# CH572SFR register map
Vendor: WCH Ltd.; Series: CH572; File version: 1.1
CPU: RISC-V r0p0, little endian, no MPU, no FPU, 2 interrupt priority bits
Registers are 32-bit, read-write, reset 0x0 unless marked. A register's access mark holds for its fields unless they carry their own. Offsets are from the block's base; [hi:lo] are bit positions.

## TMR — Timer register
Base 0x40002400
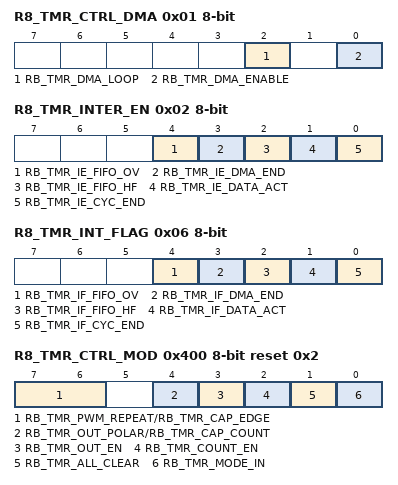
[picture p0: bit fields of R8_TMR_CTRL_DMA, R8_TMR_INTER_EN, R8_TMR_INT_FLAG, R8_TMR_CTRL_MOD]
0x01 R8_TMR_CTRL_DMA 8-bit — RO/WO, DMA control register
  [2] RB_TMR_DMA_LOOP — RW, Enable bit for DMA address loop function
  [0] RB_TMR_DMA_ENABLE — RW, DMA function enable bit
0x02 R8_TMR_INTER_EN 8-bit — RW, TMR interrupt enable
  [4] RB_TMR_IE_FIFO_OV — RW, enable interrupt for timer FIFO overflow
  [3] RB_TMR_IE_DMA_END — RW, enable interrupt for timer1/2 DMA completion
  [2] RB_TMR_IE_FIFO_HF — RW, enable interrupt for timer FIFO half (capture fifo >=4 or PWM fifo less than 3)
  [1] RB_TMR_IE_DATA_ACT — RW, enable interrupt for timer capture input action or PWM trigger
  [0] RB_TMR_IE_CYC_END — RW, enable interrupt for timer capture count timeout or PWM cycle end
0x06 R8_TMR_INT_FLAG 8-bit — RW1, TMR interrupt flag
  [4] RB_TMR_IF_FIFO_OV — RW1, interrupt flag for timer FIFO overflow
  [3] RB_TMR_IF_DMA_END — RW1, interrupt flag for timer1/2 DMA completion
  [2] RB_TMR_IF_FIFO_HF — RW1, interrupt flag for timer FIFO half (capture fifo >=4 or PWM fifo less than 3
  [1] RB_TMR_IF_DATA_ACT — RW1, interrupt flag for timer capture input action or PWM trigger
  [0] RB_TMR_IF_CYC_END — RW1, interrupt flag for timer capture count timeout or PWM cycle end
0x07 R8_TMR_FIFO_COUNT 8-bit ro reset not defined — RO, TMR FIFO count status
  [3:0] R8_TMR_FIFO_COUNT — R0,TMR FIFO count status
0x08 R32_TMR_COUNT ro reset not defined — RO, TMR current count
  [25:0] R32_TMR_COUNT — RW1,TMR current count
0x0C R32_TMR_CNT_END reset not defined — RW, TMR end count value, only low 26 bit
  [31:0] R32_TMR_CNT_END — RW1,TMR end count value
0x10 R32_TMR_FIFO ro reset not defined — RO/WO, TMR FIFO register, only low 26 bit
  [31:0] R32_TMR_FIFO — RW1,TMR FIFO register
0x14 R32_TMR_DMA_NOW ro reset not defined — RO, DMA current buffer address
  [14:2] RB_TMR_DMA_NOW — RW, DMA data buffer current address
0x18 R32_TMR_DMA_BEG reset not defined — RW, DMA start buffer address
  [14:2] RB_TMR_DMA_BEG — RW, The starting address of the DMA data buffer must be aligned with 4 bytes
0x1C R32_TMR_DMA_END reset not defined — RW, DMA end buffer address
  [14:2] RB_TMR_DMA_END — RW, DMA data buffer end address (excluding), the address must be aligned with 4 bytes
0x400 R8_TMR_CTRL_MOD 8-bit reset 0x2 — RW, TMR mode control
  [7:6] RB_TMR_PWM_REPEAT/RB_TMR_CAP_EDGE — RW, timer PWM repeat mode: 00=1, 01=4, 10=8, 11-16;RW, timer capture edge mode: 00=disable, 01=edge change, 10=fall to fall, 11-rise to rise
  [4] RB_TMR_OUT_POLAR/RB_TMR_CAP_COUNT — RW, timer PWM output polarity: 0=default low and high action, 1=default high and low action;RW, count sub-mode if RB_TMR_MODE_IN=1: 0=capture, 1=count
  [3] RB_TMR_OUT_EN — RW, timer output enable
  [2] RB_TMR_COUNT_EN — RW, timer count enable
  [1] RB_TMR_ALL_CLEAR — RW, force clear timer FIFO and count
  [0] RB_TMR_MODE_IN — RW, timer in mode: 0=timer/PWM, 1=capture/count

## UART
Base 0x40003400
0x00 R8_UART_MCR 8-bit — RW, UART modem control
  [3] RB_MCR_OUT2/RB_MCR_INT_OE — RW, UART control OUT2/UART interrupt output enable
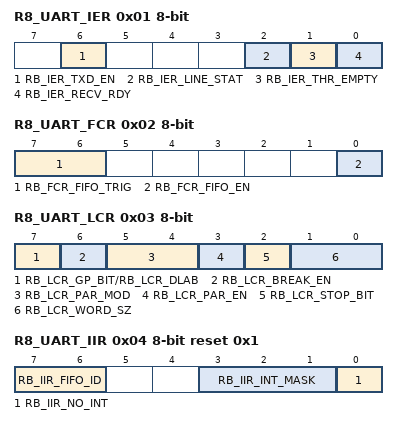
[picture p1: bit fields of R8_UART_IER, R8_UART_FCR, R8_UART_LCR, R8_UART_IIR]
0x01 R8_UART_IER 8-bit — RW, UART interrupt enable
  [6] RB_IER_TXD_EN — RW, UART TXD pin enable
  [2] RB_IER_LINE_STAT — RW, UART interrupt enable for receiver line status
  [1] RB_IER_THR_EMPTY — RW, UART interrupt enable for THR empty
  [0] RB_IER_RECV_RDY — RW, UART interrupt enable for receiver data ready
0x02 R8_UART_FCR 8-bit — RW, UART FIFO control
  [7:6] RB_FCR_FIFO_TRIG — RW, UART receiver FIFO trigger level: 00-1byte, 01-2bytes, 10-4bytes, 11-7bytes
  [0] RB_FCR_FIFO_EN — RW, UART FIFO enable
0x03 R8_UART_LCR 8-bit — RW, UART line control
  [7] RB_LCR_GP_BIT/RB_LCR_DLAB — RW, UART general purpose bit;RW, UART reserved bit
  [6] RB_LCR_BREAK_EN — RW, UART break control enable
  [5:4] RB_LCR_PAR_MOD — RW, UART parity mode: 00-odd, 01-even, 10-mark, 11-space
  [3] RB_LCR_PAR_EN — RW, UART parity enable
  [2] RB_LCR_STOP_BIT — RW, UART stop bit length: 0-1bit, 1-2bit
  [1:0] RB_LCR_WORD_SZ — RW, UART word bit length: 00-5bit, 01-6bit, 10-7bit, 11-8bit
0x04 R8_UART_IIR 8-bit ro reset 0x1 — RO, UART interrupt identification
  [7:6] RB_IIR_FIFO_ID — RO, UART FIFO enabled flag
  [3:1] RB_IIR_INT_MASK — RO, UART interrupt flag bit mask
  [0] RB_IIR_NO_INT — RO, UART no interrupt flag: 0=interrupt action, 1=no interrupt
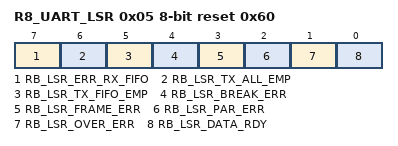
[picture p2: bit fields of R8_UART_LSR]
0x05 R8_UART_LSR 8-bit ro reset 0x60 — RO, UART line status
  [7] RB_LSR_ERR_RX_FIFO — RO, indicate error in UART receiver fifo
  [6] RB_LSR_TX_ALL_EMP — RO, UART transmitter all empty status
  [5] RB_LSR_TX_FIFO_EMP — RO, UART transmitter fifo empty status
  [4] RB_LSR_BREAK_ERR — RZ, UART receiver break error
  [3] RB_LSR_FRAME_ERR — RZ, UART receiver frame error
  [2] RB_LSR_PAR_ERR — RZ, UART receiver parity error
  [1] RB_LSR_OVER_ERR — RZ, UART receiver overrun error
  [0] RB_LSR_DATA_RDY — RO, UART receiver fifo data ready status
0x08 R8_UART_RBR 8-bit ro reset not defined — RO, UART receiver buffer, receiving byte
0x08 R8_UART_THR 8-bit wo reset not defined — WO, UART transmitter holding, transmittal byte
  [7:0] R8_UART_RBR
0x0A R8_UART_RFC 8-bit ro — RO, UART receiver FIFO count
0x0B R8_UART_TFC 8-bit ro — RO, UART transmitter FIFO count
  [7:0] R8_UART_TFC — RO, UART receiver FIFO count
0x0C R16_UART_DL 16-bit reset not defined — RW, UART divisor latch
0x0E R8_UART_DIV 8-bit reset not defined — RW, UART pre-divisor latch byte, only low 7 bit, from 1 to 128
